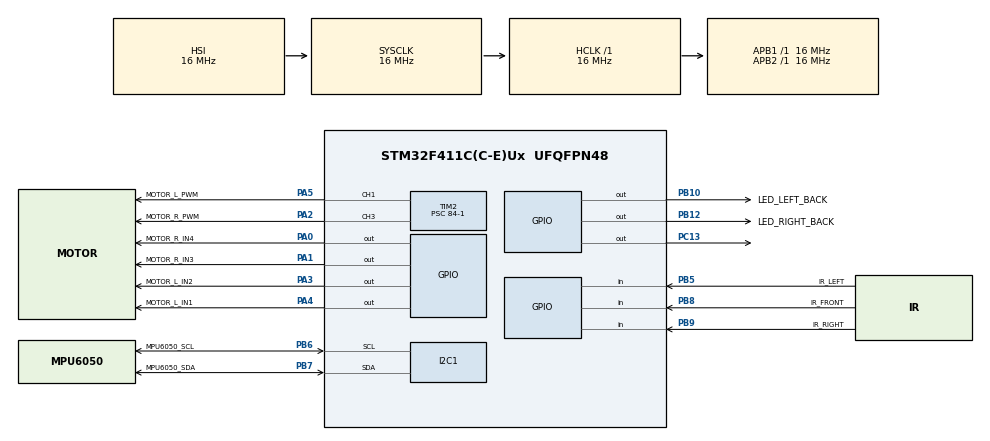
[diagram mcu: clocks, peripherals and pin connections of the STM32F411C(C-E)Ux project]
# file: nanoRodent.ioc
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Mcu.Family=STM32F4
Mcu.Name=STM32F411C(C-E)Ux
Mcu.Package=UFQFPN48
NVIC.PriorityGroup=NVIC_PRIORITYGROUP_4
PA0-WKUP.GPIO_Label=MOTOR_R_IN4
PA0-WKUP.Signal=GPIO_Output
PA1.GPIO_Label=MOTOR_R_IN3
PA1.Signal=GPIO_Output
PA2.GPIO_Label=MOTOR_R_PWM
PA2.Signal=S_TIM2_CH3
PA3.GPIO_Label=MOTOR_L_IN2
PA3.Signal=GPIO_Output
PA4.GPIO_Label=MOTOR_L_IN1
PA4.Signal=GPIO_Output
PA5.GPIO_Label=MOTOR_L_PWM
PA5.Signal=S_TIM2_CH1_ETR
PB10.GPIO_Label=LED_LEFT_BACK
PB10.Signal=GPIO_Output
PB12.GPIO_Label=LED_RIGHT_BACK
PB12.Signal=GPIO_Output
PB5.GPIO_Label=IR_LEFT
PB5.Signal=GPIO_Input
PB6.GPIO_Label=MPU6050_SCL
PB6.Mode=I2C
PB6.Signal=I2C1_SCL
PB7.GPIO_Label=MPU6050_SDA
PB7.Mode=I2C
PB7.Signal=I2C1_SDA
PB8.GPIO_Label=IR_FRONT
PB8.Signal=GPIO_Input
PB9.GPIO_Label=IR_RIGHT
PB9.Signal=GPIO_Input
PC13-ANTI_TAMP.Signal=GPIO_Output
PH0\ -\ OSC_IN.Mode=HSE-External-Oscillator
PH0\ -\ OSC_IN.Signal=RCC_OSC_IN
PH1\ -\ OSC_OUT.Mode=HSE-External-Oscillator
PH1\ -\ OSC_OUT.Signal=RCC_OSC_OUT
ProjectManager.HeapSize=0x200
ProjectManager.StackSize=0x400
ProjectManager.TargetToolchain=STM32CubeIDE
RCC.AHBFreq_Value=16000000
RCC.APB1Freq_Value=16000000
RCC.APB2Freq_Value=16000000
RCC.CortexFreq_Value=16000000
RCC.HSE_VALUE=25000000
RCC.HSI_VALUE=16000000
RCC.LSE_VALUE=32768
RCC.SYSCLKFreq_VALUE=16000000
RCC.VCOOutputFreq_Value=192000000
SH.S_TIM2_CH1_ETR.0=TIM2_CH1,PWM Generation1 CH1
SH.S_TIM2_CH3.0=TIM2_CH3,PWM Generation3 CH3
TIM2.Channel-PWM\ Generation1\ CH1=TIM_CHANNEL_1
TIM2.Channel-PWM\ Generation3\ CH3=TIM_CHANNEL_3
TIM2.Prescaler=84-1
VP_TIM2_VS_ClockSourceINT.Mode=Internal
board=custom

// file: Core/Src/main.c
/* USER CODE BEGIN Header */
/**
  ******************************************************************************
  * @file           : main.c
  * @brief          : Main program body
  ******************************************************************************
  * @attention
  *
  * Copyright (c) 2026 STMicroelectronics.
  * All rights reserved.
  *
  * This software is licensed under terms that can be found in the LICENSE file
  * in the root directory of this software component.
  * If no LICENSE file comes with this software, it is provided AS-IS.
  *
  ******************************************************************************
  */
/* USER CODE END Header */
#include "main.h"
#include "motor_control.h"

I2C_HandleTypeDef hi2c1;

TIM_HandleTypeDef htim2;

void SystemClock_Config(void);
static void MX_GPIO_Init(void);
static void MX_I2C1_Init(void);
static void MX_TIM2_Init(void);

int main(void)
{

  /* MCU Configuration--------------------------------------------------------*/

  /* Reset of all peripherals, Initializes the Flash interface and the Systick. */
  HAL_Init();

  /* Configure the system clock */
  SystemClock_Config();

  /* Initialize all configured peripherals */
  MX_GPIO_Init();
  MX_I2C1_Init();
  MX_TIM2_Init();

  /* Infinite loop */
  while (1)
  {

    /* USER CODE BEGIN 3 */
	  //Drive both motors forward at 50% speed
	  Set_Left_Motor(1, 500);
	  Set_Right_Motor(1, 500);

	  HAL_GPIO_TogglePin(GPIOC, GPIO_PIN_13);
	  HAL_Delay(2000);
  }
  /* USER CODE END 3 */
}

void SystemClock_Config(void)
{
  RCC_OscInitTypeDef RCC_OscInitStruct = {0};
  RCC_ClkInitTypeDef RCC_ClkInitStruct = {0};

  /** Configure the main internal regulator output voltage
  */
  __HAL_RCC_PWR_CLK_ENABLE();
  __HAL_PWR_VOLTAGESCALING_CONFIG(PWR_REGULATOR_VOLTAGE_SCALE1);

  /** Initializes the RCC Oscillators according to the specified parameters
  * in the RCC_OscInitTypeDef structure.
  */
  RCC_OscInitStruct.OscillatorType = RCC_OSCILLATORTYPE_HSI;
  RCC_OscInitStruct.HSIState = RCC_HSI_ON;
  RCC_OscInitStruct.HSICalibrationValue = RCC_HSICALIBRATION_DEFAULT;
  RCC_OscInitStruct.PLL.PLLState = RCC_PLL_NONE;
  if (HAL_RCC_OscConfig(&RCC_OscInitStruct) != HAL_OK)
  {
    Error_Handler();
  }

  /** Initializes the CPU, AHB and APB buses clocks
  */
  RCC_ClkInitStruct.ClockType = RCC_CLOCKTYPE_HCLK|RCC_CLOCKTYPE_SYSCLK
                              |RCC_CLOCKTYPE_PCLK1|RCC_CLOCKTYPE_PCLK2;
  RCC_ClkInitStruct.SYSCLKSource = RCC_SYSCLKSOURCE_HSI;
  RCC_ClkInitStruct.AHBCLKDivider = RCC_SYSCLK_DIV1;
  RCC_ClkInitStruct.APB1CLKDivider = RCC_HCLK_DIV1;
  RCC_ClkInitStruct.APB2CLKDivider = RCC_HCLK_DIV1;

  if (HAL_RCC_ClockConfig(&RCC_ClkInitStruct, FLASH_LATENCY_0) != HAL_OK)
  {
    Error_Handler();
  }
}

static void MX_I2C1_Init(void)
{

  hi2c1.Instance = I2C1;
  hi2c1.Init.ClockSpeed = 100000;
  hi2c1.Init.DutyCycle = I2C_DUTYCYCLE_2;
  hi2c1.Init.OwnAddress1 = 0;
  hi2c1.Init.AddressingMode = I2C_ADDRESSINGMODE_7BIT;
  hi2c1.Init.DualAddressMode = I2C_DUALADDRESS_DISABLE;
  hi2c1.Init.OwnAddress2 = 0;
  hi2c1.Init.GeneralCallMode = I2C_GENERALCALL_DISABLE;
  hi2c1.Init.NoStretchMode = I2C_NOSTRETCH_DISABLE;
  if (HAL_I2C_Init(&hi2c1) != HAL_OK)
  {
    Error_Handler();
  }

}

static void MX_TIM2_Init(void)
{

  TIM_ClockConfigTypeDef sClockSourceConfig = {0};
  TIM_MasterConfigTypeDef sMasterConfig = {0};
  TIM_OC_InitTypeDef sConfigOC = {0};

  htim2.Instance = TIM2;
  htim2.Init.Prescaler = 84-1;
  htim2.Init.CounterMode = TIM_COUNTERMODE_UP;
  htim2.Init.Period = 4294967295;
  htim2.Init.ClockDivision = TIM_CLOCKDIVISION_DIV1;
  htim2.Init.AutoReloadPreload = TIM_AUTORELOAD_PRELOAD_DISABLE;
  if (HAL_TIM_Base_Init(&htim2) != HAL_OK)
  {
    Error_Handler();
  }
  sClockSourceConfig.ClockSource = TIM_CLOCKSOURCE_INTERNAL;
  if (HAL_TIM_ConfigClockSource(&htim2, &sClockSourceConfig) != HAL_OK)
  {
    Error_Handler();
  }
  if (HAL_TIM_PWM_Init(&htim2) != HAL_OK)
  {
    Error_Handler();
  }
  sMasterConfig.MasterOutputTrigger = TIM_TRGO_RESET;
  sMasterConfig.MasterSlaveMode = TIM_MASTERSLAVEMODE_DISABLE;
  if (HAL_TIMEx_MasterConfigSynchronization(&htim2, &sMasterConfig) != HAL_OK)
  {
    Error_Handler();
  }
  sConfigOC.OCMode = TIM_OCMODE_PWM1;
  sConfigOC.Pulse = 0;
  sConfigOC.OCPolarity = TIM_OCPOLARITY_HIGH;
  sConfigOC.OCFastMode = TIM_OCFAST_DISABLE;
  if (HAL_TIM_PWM_ConfigChannel(&htim2, &sConfigOC, TIM_CHANNEL_1) != HAL_OK)
  {
    Error_Handler();
  }
  if (HAL_TIM_PWM_ConfigChannel(&htim2, &sConfigOC, TIM_CHANNEL_3) != HAL_OK)
  {
    Error_Handler();
  }
  HAL_TIM_MspPostInit(&htim2);

}

static void MX_GPIO_Init(void)
{
  GPIO_InitTypeDef GPIO_InitStruct = {0};

  /* GPIO Ports Clock Enable */
  __HAL_RCC_GPIOC_CLK_ENABLE();
  __HAL_RCC_GPIOH_CLK_ENABLE();
  __HAL_RCC_GPIOA_CLK_ENABLE();
  __HAL_RCC_GPIOB_CLK_ENABLE();

  /*Configure GPIO pin Output Level */
  HAL_GPIO_WritePin(GPIOC, GPIO_PIN_13, GPIO_PIN_RESET);

  /*Configure GPIO pin Output Level */
  HAL_GPIO_WritePin(GPIOA, MOTOR_R_IN4_Pin|MOTOR_R_IN3_Pin|MOTOR_L_IN2_Pin|MOTOR_L_IN1_Pin, GPIO_PIN_RESET);

  /*Configure GPIO pin Output Level */
  HAL_GPIO_WritePin(GPIOB, LED_LEFT_BACK_Pin|LED_RIGHT_BACK_Pin, GPIO_PIN_RESET);

  /*Configure GPIO pin : PC13 */
  GPIO_InitStruct.Pin = GPIO_PIN_13;
  GPIO_InitStruct.Mode = GPIO_MODE_OUTPUT_PP;
  GPIO_InitStruct.Pull = GPIO_NOPULL;
  GPIO_InitStruct.Speed = GPIO_SPEED_FREQ_LOW;
  HAL_GPIO_Init(GPIOC, &GPIO_InitStruct);

  /*Configure GPIO pins : MOTOR_R_IN4_Pin MOTOR_R_IN3_Pin MOTOR_L_IN2_Pin MOTOR_L_IN1_Pin */
  GPIO_InitStruct.Pin = MOTOR_R_IN4_Pin|MOTOR_R_IN3_Pin|MOTOR_L_IN2_Pin|MOTOR_L_IN1_Pin;
  GPIO_InitStruct.Mode = GPIO_MODE_OUTPUT_PP;
  GPIO_InitStruct.Pull = GPIO_NOPULL;
  GPIO_InitStruct.Speed = GPIO_SPEED_FREQ_LOW;
  HAL_GPIO_Init(GPIOA, &GPIO_InitStruct);

  /*Configure GPIO pins : LED_LEFT_BACK_Pin LED_RIGHT_BACK_Pin */
  GPIO_InitStruct.Pin = LED_LEFT_BACK_Pin|LED_RIGHT_BACK_Pin;
  GPIO_InitStruct.Mode = GPIO_MODE_OUTPUT_PP;
  GPIO_InitStruct.Pull = GPIO_NOPULL;
  GPIO_InitStruct.Speed = GPIO_SPEED_FREQ_LOW;
  HAL_GPIO_Init(GPIOB, &GPIO_InitStruct);

  /*Configure GPIO pins : IR_LEFT_Pin IR_FRONT_Pin IR_RIGHT_Pin */
  GPIO_InitStruct.Pin = IR_LEFT_Pin|IR_FRONT_Pin|IR_RIGHT_Pin;
  GPIO_InitStruct.Mode = GPIO_MODE_INPUT;
  GPIO_InitStruct.Pull = GPIO_NOPULL;
  HAL_GPIO_Init(GPIOB, &GPIO_InitStruct);

}

void Error_Handler(void)
{
  __disable_irq();
  while (1)
  {
  }
}
